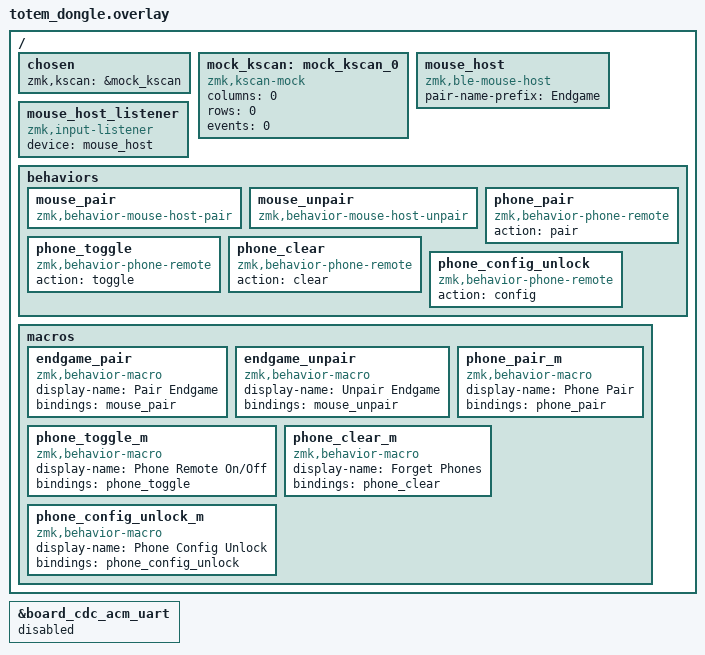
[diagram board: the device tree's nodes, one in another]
/*
 * Copyright (c) 2022 The ZMK Contributors
 *
 * SPDX-License-Identifier: MIT
 *
 * Prospector dongle: no keys, so the real matrix scan is swapped for ZMK's
 * mock kscan (dongle guide). Reuses totem.dtsi so the matrix transform and
 * Studio physical layout stay identical to the halves (the halves send
 * positions already transformed by their own col-offset).
 */

#include "totem.dtsi"

/* totem.dtsi's kscan0 has no col-gpios here (the pins belong to the
 * display), so it must not stay in the tree. */
/delete-node/ &kscan0;

/* USB is keyboard/mouse only on the dongle (it sits on a locked-down
 * workstation). The xiao_ble board always adds a CDC-ACM console port
 * (zephyr boards/seeed/xiao_ble/xiao_ble_common.dtsi includes
 * boards/common/usb/cdc_acm_serial.dtsi), with or without a Studio snippet:
 * disable it, and point nothing at it. BOARD_SERIAL_BACKEND_CDC_ACM=n in
 * Kconfig.defconfig drops the console that would use it. */
&board_cdc_acm_uart {
    status = "disabled";
};

/ {
    chosen {
        /delete-property/ zephyr,console;
        /delete-property/ zephyr,shell-uart;
        /delete-property/ zephyr,uart-mcumgr;
        /delete-property/ zephyr,bt-mon-uart;
        /delete-property/ zephyr,bt-c2h-uart;
    };
};

/ {
    chosen {
        zmk,kscan = &mock_kscan;
    };

    mock_kscan: mock_kscan_0 {
        compatible = "zmk,kscan-mock";
        columns = <0>;
        rows = <0>;
        events = <0>;
    };

    /* Endgame trackball over BLE (AJ's zmk-ble-mouse-host fork). Only the
     * central runs it, so the node and behaviors live here, not in the shared
     * keymap. */
    mouse_host: mouse_host {
        compatible = "zmk,ble-mouse-host";
        /* Pairing mode picks the first Endgame by name, not any mouse. */
        pair-name-prefix = "Endgame";
    };

    /* Plain forward into the pointing pipeline. No layer-conditional
     * processors yet (speed layers etc. are AJ's call). */
    mouse_host_listener {
        compatible = "zmk,input-listener";
        device = <&mouse_host>;
        /* Calibration knob, first hardware check: the Endgame may send hi-res
         * wheel values (its smooth scrolling, multiplier 15) that this
         * dongle reads as whole detents, so scrolling would run ~15x fast.
         * If so, uncomment (needs #include <input/processors.dtsi>):
         * input-processors = <&zip_scroll_scaler 1 15>; */
    };

    behaviors {
        mouse_pair: mouse_pair {
            compatible = "zmk,behavior-mouse-host-pair";
            #binding-cells = <0>;
        };

        mouse_unpair: mouse_unpair {
            compatible = "zmk,behavior-mouse-host-unpair";
            #binding-cells = <0>;
        };

        /* Phone remote (docs/phone-remote.md). &phone_pair opens the 60 s
         * pairing window (pressed again: cancels it); &phone_toggle switches
         * phone input on/off (remembered); &phone_clear forgets the phones. */
        phone_pair: phone_pair {
            compatible = "zmk,behavior-phone-remote";
            #binding-cells = <0>;
            action = "pair";
        };

        phone_toggle: phone_toggle {
            compatible = "zmk,behavior-phone-remote";
            #binding-cells = <0>;
            action = "toggle";
        };

        phone_clear: phone_clear {
            compatible = "zmk,behavior-phone-remote";
            #binding-cells = <0>;
            action = "clear";
        };

        /* Opens (pressed again: closes) the config window: for
         * CONFIG_TOTEM_PHONE_REMOTE_CONFIG_WINDOW_S the connected paired
         * phone may use ZMK Studio and the Flask tunnel. */
        phone_config_unlock: phone_config_unlock {
            compatible = "zmk,behavior-phone-remote";
            #binding-cells = <0>;
            action = "config";
        };
    };

    /* The module's behaviors carry no Studio metadata at the pinned ZMK (same
     * gap as &mmv/&msc), so macros make them assignable from Studio /
     * Totem-Flask. Not bound in totem.keymap: every thumb on Navigation is
     * load-bearing and AJ's live keymap lives in Studio anyway. Pair forgets
     * the old bond first, so Unpair is only for "stop reconnecting". */
    macros {
        endgame_pair: endgame_pair {
            compatible = "zmk,behavior-macro";
            display-name = "Pair Endgame";
            #binding-cells = <0>;
            bindings = <&mouse_pair>;
        };

        endgame_unpair: endgame_unpair {
            compatible = "zmk,behavior-macro";
            display-name = "Unpair Endgame";
            #binding-cells = <0>;
            bindings = <&mouse_unpair>;
        };

        /* Same reason: Studio-assignable phone remote keys, not bound in
         * totem.keymap. */
        phone_pair_m: phone_pair_m {
            compatible = "zmk,behavior-macro";
            display-name = "Phone Pair";
            #binding-cells = <0>;
            bindings = <&phone_pair>;
        };

        phone_toggle_m: phone_toggle_m {
            compatible = "zmk,behavior-macro";
            display-name = "Phone Remote On/Off";
            #binding-cells = <0>;
            bindings = <&phone_toggle>;
        };

        phone_clear_m: phone_clear_m {
            compatible = "zmk,behavior-macro";
            display-name = "Forget Phones";
            #binding-cells = <0>;
            bindings = <&phone_clear>;
        };

        phone_config_unlock_m: phone_config_unlock_m {
            compatible = "zmk,behavior-macro";
            display-name = "Phone Config Unlock";
            #binding-cells = <0>;
            bindings = <&phone_config_unlock>;
        };
    };
};
